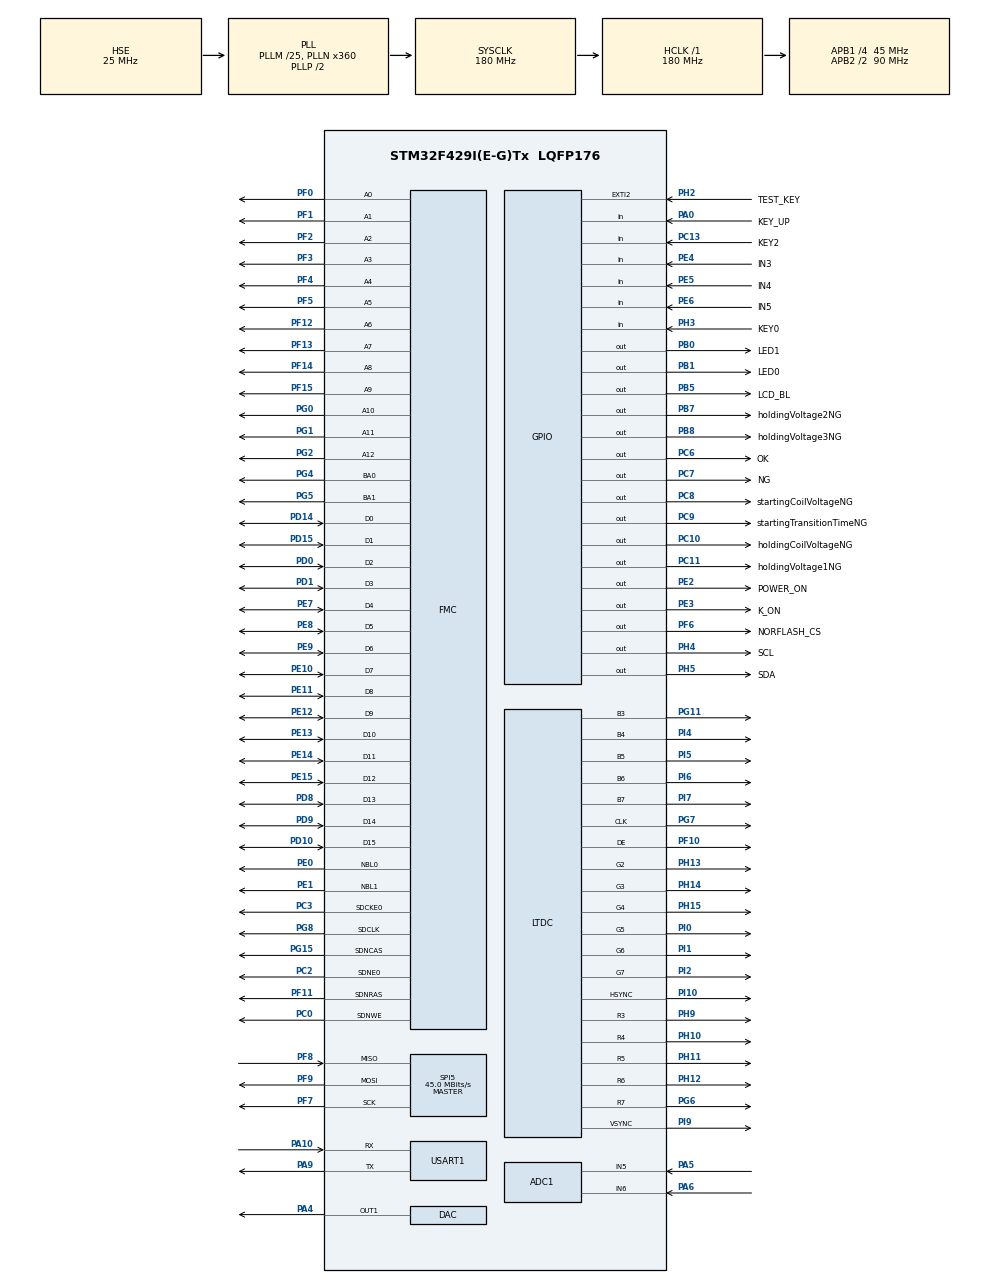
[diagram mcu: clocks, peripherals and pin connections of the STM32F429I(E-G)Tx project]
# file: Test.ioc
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ADC1.Channel-0\#ChannelRegularConversion=ADC_CHANNEL_5
ADC1.Channel-1\#ChannelRegularConversion=ADC_CHANNEL_6
ADC1.Channel-2\#ChannelRegularConversion=ADC_CHANNEL_TEMPSENSOR
ADC1.ContinuousConvMode=ENABLE
ADC1.DMAContinuousRequests=ENABLE
ADC1.EOCSelection=ADC_EOC_SEQ_CONV
ADC1.EnableAnalogWatchDog=true
ADC1.ExternalTrigConv=ADC_SOFTWARE_START
ADC1.HighThreshold=3000
ADC1.ITMode=ENABLE
ADC1.NbrOfConversion=3
ADC1.NbrOfConversionFlag=1
ADC1.Rank-0\#ChannelRegularConversion=1
ADC1.Rank-1\#ChannelRegularConversion=2
ADC1.Rank-2\#ChannelRegularConversion=3
ADC1.SamplingTime-0\#ChannelRegularConversion=ADC_SAMPLETIME_480CYCLES
ADC1.SamplingTime-1\#ChannelRegularConversion=ADC_SAMPLETIME_480CYCLES
ADC1.SamplingTime-2\#ChannelRegularConversion=ADC_SAMPLETIME_480CYCLES
ADC1.ScanConvMode=ENABLE
ADC1.WatchdogMode=ADC_ANALOGWATCHDOG_ALL_REG
ADC1.master=1
DAC.DAC_OutputBuffer=DAC_OUTPUTBUFFER_ENABLE
DMA2D.ColorMode=DMA2D_OUTPUT_RGB565
Dma.ADC1.0.Direction=DMA_PERIPH_TO_MEMORY
Dma.ADC1.0.FIFOMode=DMA_FIFOMODE_DISABLE
Dma.ADC1.0.Instance=DMA2_Stream0
Dma.ADC1.0.MemDataAlignment=DMA_MDATAALIGN_WORD
Dma.ADC1.0.MemInc=DMA_MINC_ENABLE
Dma.ADC1.0.Mode=DMA_CIRCULAR
Dma.ADC1.0.PeriphDataAlignment=DMA_PDATAALIGN_WORD
Dma.ADC1.0.PeriphInc=DMA_PINC_DISABLE
Dma.ADC1.0.Priority=DMA_PRIORITY_MEDIUM
Dma.Request0=ADC1
Dma.Request1=USART1_RX
Dma.Request2=USART1_TX
Dma.USART1_RX.1.Direction=DMA_PERIPH_TO_MEMORY
Dma.USART1_RX.1.FIFOMode=DMA_FIFOMODE_DISABLE
Dma.USART1_RX.1.Instance=DMA2_Stream2
Dma.USART1_RX.1.MemDataAlignment=DMA_MDATAALIGN_BYTE
Dma.USART1_RX.1.MemInc=DMA_MINC_ENABLE
Dma.USART1_RX.1.Mode=DMA_NORMAL
Dma.USART1_RX.1.PeriphDataAlignment=DMA_PDATAALIGN_BYTE
Dma.USART1_RX.1.PeriphInc=DMA_PINC_DISABLE
Dma.USART1_RX.1.Priority=DMA_PRIORITY_VERY_HIGH
Dma.USART1_TX.2.Direction=DMA_MEMORY_TO_PERIPH
Dma.USART1_TX.2.FIFOMode=DMA_FIFOMODE_DISABLE
Dma.USART1_TX.2.Instance=DMA2_Stream7
Dma.USART1_TX.2.MemDataAlignment=DMA_MDATAALIGN_BYTE
Dma.USART1_TX.2.MemInc=DMA_MINC_ENABLE
Dma.USART1_TX.2.Mode=DMA_NORMAL
Dma.USART1_TX.2.PeriphDataAlignment=DMA_PDATAALIGN_BYTE
Dma.USART1_TX.2.PeriphInc=DMA_PINC_DISABLE
Dma.USART1_TX.2.Priority=DMA_PRIORITY_VERY_HIGH
FATFS._CODE_PAGE=936
FATFS._FS_EXFAT=1
FATFS._FS_NORTC=0
FATFS._FS_RPATH=2
FATFS._LFN_UNICODE=0
FATFS._MAX_SS=4096
FATFS._NORTC_MDAY=25
FATFS._NORTC_MON=5
FATFS._NORTC_YEAR=2026
FATFS._USE_LFN=3
FMC.CASLatency1=FMC_SDRAM_CAS_LATENCY_3
FMC.ColumnBitsNumber1=FMC_SDRAM_COLUMN_BITS_NUM_9
FMC.ExitSelfRefreshDelay1=8
FMC.LoadToActiveDelay1=2
FMC.RCDDelay1=2
FMC.RPDelay1=2
FMC.RPDelay2=2
FMC.ReadBurst1=FMC_SDRAM_RBURST_ENABLE
FMC.ReadBurst2=FMC_SDRAM_RBURST_ENABLE
FMC.ReadPipeDelay1=FMC_SDRAM_RPIPE_DELAY_1
FMC.ReadPipeDelay2=FMC_SDRAM_RPIPE_DELAY_1
FMC.RowCycleDelay1=6
FMC.RowCycleDelay2=6
FMC.SDClockPeriod1=FMC_SDRAM_CLOCK_PERIOD_2
FMC.SDClockPeriod2=FMC_SDRAM_CLOCK_PERIOD_2
FMC.SelfRefreshTime1=6
FMC.WriteProtection1=FMC_SDRAM_WRITE_PROTECTION_DISABLE
FMC.WriteRecoveryTime1=4
FREERTOS.BinarySemaphores01=adcConversionCompleteSemaphore,Dynamic,NULL,;testStartSemaphore,Dynamic,NULL,Depleted;clearDisplaySemaphore,Dynamic,NULL,Depleted
FREERTOS.Tasks01=touchGFX,24,4096,TouchGFX_Task,As weak,NULL,Dynamic,NULL,NULL;adcTask,32,256,adcStartTask,Default,NULL,Dynamic,NULL,NULL;usart1Data,24,512,usart1DataTask,Default,NULL,Dynamic,NULL,NULL;dacTask,24,256,dacStartTask,Default,NULL,Dynamic,NULL,NULL;testTask,24,512,testStartTask,Default,NULL,Dynamic,NULL,NULL;vTaskSDCard,8,1024,SDCardManager,Default,NULL,Dynamic,NULL,NULL
FREERTOS.configENABLE_FPU=1
FREERTOS.configLIBRARY_MAX_SYSCALL_INTERRUPT_PRIORITY=2
FREERTOS.configTOTAL_HEAP_SIZE=102400
FREERTOS.configUSE_NEWLIB_REENTRANT=1
FREERTOS.copyHeapFile=1
LTDC.ActiveH=600
LTDC.ActiveW=1024
LTDC.Alpha_L0=255
LTDC.FBStartAdress_L0=0xC0000000
LTDC.HBP=140
LTDC.HFP=160
LTDC.HSync=20
LTDC.ImageHeight_L0=600
LTDC.ImageWidth_L0=1024
LTDC.Layers=0
LTDC.PixelFormat_L0=LTDC_PIXEL_FORMAT_RGB565
LTDC.VBP=20
LTDC.VFP=12
LTDC.VSync=3
LTDC.WindowX1_L0=1024
LTDC.WindowY1_L0=600
Mcu.Family=STM32F4
Mcu.Name=STM32F429I(E-G)Tx
Mcu.Package=LQFP176
NVIC.ADC_IRQn=true\:5\:0\:true\:false\:true\:true\:true\:true\:true
NVIC.DMA2D_IRQn=true\:9\:0\:true\:false\:true\:true\:true\:true\:true
NVIC.DMA2_Stream0_IRQn=true\:5\:0\:true\:false\:true\:true\:false\:true\:true
NVIC.DMA2_Stream2_IRQn=true\:6\:0\:true\:false\:true\:true\:false\:true\:true
NVIC.DMA2_Stream7_IRQn=true\:6\:0\:true\:false\:true\:true\:false\:true\:true
NVIC.EXTI2_IRQn=true\:2\:0\:false\:false\:true\:true\:true\:true\:true
NVIC.LTDC_IRQn=true\:9\:0\:true\:false\:true\:true\:true\:true\:true
NVIC.PriorityGroup=NVIC_PRIORITYGROUP_4
NVIC.TIM6_DAC_IRQn=true\:6\:0\:true\:false\:true\:true\:true\:true\:true
NVIC.TIM7_IRQn=true\:0\:0\:false\:false\:true\:false\:false\:true\:true
NVIC.TimeBase=TIM7_IRQn
NVIC.TimeBaseIP=TIM7
NVIC.USART1_IRQn=true\:6\:0\:true\:false\:true\:true\:true\:true\:true
PA0/WKUP.GPIO_Label=KEY_UP
PA0/WKUP.GPIO_PuPd=GPIO_PULLDOWN
PA0/WKUP.Signal=GPIO_Input
PA10.Mode=Asynchronous
PA10.Signal=USART1_RX
PA13.Mode=Serial_Wire
PA13.Signal=SYS_JTMS-SWDIO
PA14.Mode=Serial_Wire
PA14.Signal=SYS_JTCK-SWCLK
PA4.Signal=COMP_DAC1_group
PA5.Signal=ADCx_IN5
PA6.Signal=ADCx_IN6
PA9.Mode=Asynchronous
PA9.Signal=USART1_TX
PB0.GPIO_Label=LED1
PB0.GPIO_PuPd=GPIO_PULLUP
PB0.GPIO_Speed=GPIO_SPEED_FREQ_LOW
PB0.PinState=GPIO_PIN_SET
PB0.Signal=GPIO_Output
PB1.GPIO_Label=LED0
PB1.GPIO_PuPd=GPIO_PULLUP
PB1.GPIO_Speed=GPIO_SPEED_FREQ_LOW
PB1.PinState=GPIO_PIN_SET
PB1.Signal=GPIO_Output
PB5.GPIO_Label=LCD_BL
PB5.GPIO_PuPd=GPIO_PULLUP
PB5.GPIO_Speed=GPIO_SPEED_FREQ_HIGH
PB5.Signal=GPIO_Output
PB7.GPIO_Label=holdingVoltage2NG
PB7.GPIO_ModeDefaultOutputPP=GPIO_MODE_OUTPUT_PP
PB7.GPIO_PuPd=GPIO_PULLUP
PB7.GPIO_Speed=GPIO_SPEED_FREQ_HIGH
PB7.PinState=GPIO_PIN_SET
PB7.Signal=GPIO_Output
PB8.GPIO_Label=holdingVoltage3NG
PB8.GPIO_PuPd=GPIO_PULLUP
PB8.GPIO_Speed=GPIO_SPEED_FREQ_HIGH
PB8.PinState=GPIO_PIN_SET
PB8.Signal=GPIO_Output
PC0.Signal=FMC_SDNWE
PC10.GPIO_Label=holdingCoilVoltageNG
PC10.GPIO_PuPd=GPIO_PULLUP
PC10.GPIO_Speed=GPIO_SPEED_FREQ_HIGH
PC10.Signal=GPIO_Output
PC11.GPIO_Label=holdingVoltage1NG
PC11.GPIO_PuPd=GPIO_PULLUP
PC11.GPIO_Speed=GPIO_SPEED_FREQ_HIGH
PC11.Signal=GPIO_Output
PC13.GPIO_Label=KEY2
PC13.GPIO_PuPd=GPIO_PULLUP
PC13.Signal=GPIO_Input
PC14/OSC32_IN.Mode=LSE-External-Oscillator
PC14/OSC32_IN.Signal=RCC_OSC32_IN
PC15/OSC32_OUT.Mode=LSE-External-Oscillator
PC15/OSC32_OUT.Signal=RCC_OSC32_OUT
PC2.Mode=SdramChipSelect1_1
PC2.Signal=FMC_SDNE0
PC3.Mode=SdramChipSelect1_1
PC3.Signal=FMC_SDCKE0
PC6.GPIO_Label=OK
PC6.GPIO_PuPd=GPIO_PULLUP
PC6.GPIO_Speed=GPIO_SPEED_FREQ_HIGH
PC6.PinState=GPIO_PIN_SET
PC6.Signal=GPIO_Output
PC7.GPIO_Label=NG
PC7.GPIO_PuPd=GPIO_PULLUP
PC7.GPIO_Speed=GPIO_SPEED_FREQ_HIGH
PC7.PinState=GPIO_PIN_SET
PC7.Signal=GPIO_Output
PC8.GPIO_Label=startingCoilVoltageNG
PC8.GPIO_ModeDefaultOutputPP=GPIO_MODE_OUTPUT_PP
PC8.GPIO_PuPd=GPIO_PULLUP
PC8.GPIO_Speed=GPIO_SPEED_FREQ_HIGH
PC8.Signal=GPIO_Output
PC9.GPIO_Label=startingTransitionTimeNG
PC9.GPIO_PuPd=GPIO_PULLUP
PC9.GPIO_Speed=GPIO_SPEED_FREQ_HIGH
PC9.Signal=GPIO_Output
PD0.Signal=FMC_D2_DA2
PD1.Signal=FMC_D3_DA3
PD10.Signal=FMC_D15_DA15
PD14.Signal=FMC_D0_DA0
PD15.Signal=FMC_D1_DA1
PD8.Signal=FMC_D13_DA13
PD9.Signal=FMC_D14_DA14
PE0.Signal=FMC_NBL0
PE1.Signal=FMC_NBL1
PE10.Signal=FMC_D7_DA7
PE11.Signal=FMC_D8_DA8
PE12.Signal=FMC_D9_DA9
PE13.Signal=FMC_D10_DA10
PE14.Signal=FMC_D11_DA11
PE15.Signal=FMC_D12_DA12
PE2.GPIO_Label=POWER_ON
PE2.GPIO_PuPd=GPIO_PULLUP
PE2.GPIO_Speed=GPIO_SPEED_FREQ_LOW
PE2.PinState=GPIO_PIN_SET
PE2.Signal=GPIO_Output
PE3.GPIO_Label=K_ON
PE3.GPIO_ModeDefaultOutputPP=GPIO_MODE_OUTPUT_PP
PE3.GPIO_PuPd=GPIO_PULLDOWN
PE3.GPIO_Speed=GPIO_SPEED_FREQ_LOW
PE3.PinState=GPIO_PIN_RESET
PE3.Signal=GPIO_Output
PE4.GPIO_Label=IN3
PE4.GPIO_PuPd=GPIO_PULLUP
PE4.Signal=GPIO_Input
PE5.GPIO_Label=IN4
PE5.GPIO_PuPd=GPIO_PULLUP
PE5.Signal=GPIO_Input
PE6.GPIO_Label=IN5
PE6.GPIO_PuPd=GPIO_PULLUP
PE6.Signal=GPIO_Input
PE7.Signal=FMC_D4_DA4
PE8.Signal=FMC_D5_DA5
PE9.Signal=FMC_D6_DA6
PF0.Signal=FMC_A0
PF1.Signal=FMC_A1
PF10.GPIO_Speed=GPIO_SPEED_FREQ_VERY_HIGH
PF10.Mode=RGB565
PF10.Signal=LTDC_DE
PF11.Signal=FMC_SDNRAS
PF12.Signal=FMC_A6
PF13.Signal=FMC_A7
PF14.Signal=FMC_A8
PF15.Signal=FMC_A9
PF2.Signal=FMC_A2
PF3.Signal=FMC_A3
PF4.Signal=FMC_A4
PF5.Signal=FMC_A5
PF6.GPIO_Label=NORFLASH_CS
PF6.GPIO_PuPd=GPIO_PULLUP
PF6.GPIO_Speed=GPIO_SPEED_FREQ_HIGH
PF6.PinState=GPIO_PIN_SET
PF6.Signal=GPIO_Output
PF7.Mode=Full_Duplex_Master
PF7.Signal=SPI5_SCK
PF8.Mode=Full_Duplex_Master
PF8.Signal=SPI5_MISO
PF9.Mode=Full_Duplex_Master
PF9.Signal=SPI5_MOSI
PG0.Signal=FMC_A10
PG1.Signal=FMC_A11
PG11.GPIO_Speed=GPIO_SPEED_FREQ_VERY_HIGH
PG11.Mode=RGB565
PG11.Signal=LTDC_B3
PG15.Signal=FMC_SDNCAS
PG2.Signal=FMC_A12
PG4.Signal=FMC_A14_BA0
PG5.Signal=FMC_A15_BA1
PG6.GPIO_Speed=GPIO_SPEED_FREQ_VERY_HIGH
PG6.Mode=RGB565
PG6.Signal=LTDC_R7
PG7.GPIO_Speed=GPIO_SPEED_FREQ_VERY_HIGH
PG7.Mode=RGB565
PG7.Signal=LTDC_CLK
PG8.Signal=FMC_SDCLK
PH0/OSC_IN.Mode=HSE-External-Oscillator
PH0/OSC_IN.Signal=RCC_OSC_IN
PH1/OSC_OUT.Mode=HSE-External-Oscillator
PH1/OSC_OUT.Signal=RCC_OSC_OUT
PH10.GPIO_Speed=GPIO_SPEED_FREQ_VERY_HIGH
PH10.Mode=RGB565
PH10.Signal=LTDC_R4
PH11.GPIO_Speed=GPIO_SPEED_FREQ_VERY_HIGH
PH11.Mode=RGB565
PH11.Signal=LTDC_R5
PH12.GPIO_Speed=GPIO_SPEED_FREQ_VERY_HIGH
PH12.Mode=RGB565
PH12.Signal=LTDC_R6
PH13.GPIO_Speed=GPIO_SPEED_FREQ_VERY_HIGH
PH13.Mode=RGB565
PH13.Signal=LTDC_G2
PH14.GPIO_Speed=GPIO_SPEED_FREQ_VERY_HIGH
PH14.Mode=RGB565
PH14.Signal=LTDC_G3
PH15.GPIO_Speed=GPIO_SPEED_FREQ_VERY_HIGH
PH15.Mode=RGB565
PH15.Signal=LTDC_G4
PH2.GPIO_Label=TEST_KEY
PH2.GPIO_ModeDefaultEXTI=GPIO_MODE_IT_FALLING
PH2.GPIO_PuPd=GPIO_PULLUP
PH2.Signal=GPXTI2
PH3.GPIO_Label=KEY0
PH3.GPIO_PuPd=GPIO_PULLUP
PH3.Signal=GPIO_Input
PH4.GPIO_Label=SCL
PH4.GPIO_ModeDefaultOutputPP=GPIO_MODE_OUTPUT_OD
PH4.GPIO_PuPd=GPIO_PULLUP
PH4.GPIO_Speed=GPIO_SPEED_FREQ_HIGH
PH4.PinState=GPIO_PIN_SET
PH4.Signal=GPIO_Output
PH5.GPIO_Label=SDA
PH5.GPIO_ModeDefaultOutputPP=GPIO_MODE_OUTPUT_OD
PH5.GPIO_PuPd=GPIO_PULLUP
PH5.GPIO_Speed=GPIO_SPEED_FREQ_HIGH
PH5.PinState=GPIO_PIN_SET
PH5.Signal=GPIO_Output
PH9.GPIO_Speed=GPIO_SPEED_FREQ_VERY_HIGH
PH9.Mode=RGB565
PH9.Signal=LTDC_R3
PI0.GPIO_Speed=GPIO_SPEED_FREQ_VERY_HIGH
PI0.Mode=RGB565
PI0.Signal=LTDC_G5
PI1.GPIO_Speed=GPIO_SPEED_FREQ_VERY_HIGH
PI1.Mode=RGB565
PI1.Signal=LTDC_G6
PI10.GPIO_Speed=GPIO_SPEED_FREQ_VERY_HIGH
PI10.Mode=RGB565
PI10.Signal=LTDC_HSYNC
PI2.GPIO_Speed=GPIO_SPEED_FREQ_VERY_HIGH
PI2.Mode=RGB565
PI2.Signal=LTDC_G7
PI4.GPIO_Speed=GPIO_SPEED_FREQ_VERY_HIGH
PI4.Mode=RGB565
PI4.Signal=LTDC_B4
PI5.GPIO_Speed=GPIO_SPEED_FREQ_VERY_HIGH
PI5.Mode=RGB565
PI5.Signal=LTDC_B5
PI6.GPIO_Speed=GPIO_SPEED_FREQ_VERY_HIGH
PI6.Mode=RGB565
PI6.Signal=LTDC_B6
PI7.GPIO_Speed=GPIO_SPEED_FREQ_VERY_HIGH
PI7.Mode=RGB565
PI7.Signal=LTDC_B7
PI9.GPIO_Speed=GPIO_SPEED_FREQ_VERY_HIGH
PI9.Mode=RGB565
PI9.Signal=LTDC_VSYNC
ProjectManager.HeapSize=0x2000
ProjectManager.StackSize=0x1000
ProjectManager.TargetToolchain=STM32CubeIDE
RCC.48MHZClocksFreq_Value=45000000
RCC.AHBFreq_Value=180000000
RCC.APB1CLKDivider=RCC_HCLK_DIV4
RCC.APB1Freq_Value=45000000
RCC.APB1TimFreq_Value=90000000
RCC.APB2CLKDivider=RCC_HCLK_DIV2
RCC.APB2Freq_Value=90000000
RCC.APB2TimFreq_Value=180000000
RCC.CortexFreq_Value=180000000
RCC.HCLKFreq_Value=180000000
RCC.HSE_VALUE=25000000
RCC.HSI_VALUE=16000000
RCC.PLLM=25
RCC.PLLN=360
RCC.PLLQ=8
RCC.PLLSAIN=168
RCC.PLLSAIR=2
RCC.PLLSourceVirtual=RCC_PLLSOURCE_HSE
RCC.RCC_RTC_Clock_Source=RCC_RTCCLKSOURCE_LSE
RCC.RCC_RTC_Clock_SourceVirtual=RCC_RTCCLKSOURCE_LSE
RCC.SYSCLKFreq_VALUE=180000000
RCC.SYSCLKSource=RCC_SYSCLKSOURCE_PLLCLK
RCC.VCOOutputFreq_Value=360000000
RTC.Alarm=RTC_ALARM_A
RTC.Alarm_B=RTC_ALARM_B
RTC.Date=25
RTC.Format=RTC_FORMAT_BIN
RTC.Hours=15
RTC.Minutes=25
RTC.Month=RTC_MONTH_MAY
RTC.WeekDay=RTC_WEEKDAY_SUNDAY
RTC.Year=25
SH.ADCx_IN5.0=ADC1_IN5,IN5
SH.ADCx_IN6.0=ADC1_IN6,IN6
SH.COMP_DAC1_group.0=DAC_OUT1,DAC_OUT1
SH.FMC_A0.0=FMC_A0,13b-sda1
SH.FMC_A1.0=FMC_A1,13b-sda1
SH.FMC_A10.0=FMC_A10,13b-sda1
SH.FMC_A11.0=FMC_A11,13b-sda1
SH.FMC_A12.0=FMC_A12,13b-sda1
SH.FMC_A14_BA0.0=FMC_BA0,FourSdramBanks1
SH.FMC_A15_BA1.0=FMC_BA1,FourSdramBanks1
SH.FMC_A2.0=FMC_A2,13b-sda1
SH.FMC_A3.0=FMC_A3,13b-sda1
SH.FMC_A4.0=FMC_A4,13b-sda1
SH.FMC_A5.0=FMC_A5,13b-sda1
SH.FMC_A6.0=FMC_A6,13b-sda1
SH.FMC_A7.0=FMC_A7,13b-sda1
SH.FMC_A8.0=FMC_A8,13b-sda1
SH.FMC_A9.0=FMC_A9,13b-sda1
SH.FMC_D0_DA0.0=FMC_D0,sd-16b-d1
SH.FMC_D10_DA10.0=FMC_D10,sd-16b-d1
SH.FMC_D11_DA11.0=FMC_D11,sd-16b-d1
SH.FMC_D12_DA12.0=FMC_D12,sd-16b-d1
SH.FMC_D13_DA13.0=FMC_D13,sd-16b-d1
SH.FMC_D14_DA14.0=FMC_D14,sd-16b-d1
SH.FMC_D15_DA15.0=FMC_D15,sd-16b-d1
SH.FMC_D1_DA1.0=FMC_D1,sd-16b-d1
SH.FMC_D2_DA2.0=FMC_D2,sd-16b-d1
SH.FMC_D3_DA3.0=FMC_D3,sd-16b-d1
SH.FMC_D4_DA4.0=FMC_D4,sd-16b-d1
SH.FMC_D5_DA5.0=FMC_D5,sd-16b-d1
SH.FMC_D6_DA6.0=FMC_D6,sd-16b-d1
SH.FMC_D7_DA7.0=FMC_D7,sd-16b-d1
SH.FMC_D8_DA8.0=FMC_D8,sd-16b-d1
SH.FMC_D9_DA9.0=FMC_D9,sd-16b-d1
SH.FMC_NBL0.0=FMC_NBL0,Sd2ByteEnable1
SH.FMC_NBL1.0=FMC_NBL1,Sd2ByteEnable1
SH.FMC_SDCLK.0=FMC_SDCLK,13b-sda1
SH.FMC_SDNCAS.0=FMC_SDNCAS,13b-sda1
SH.FMC_SDNRAS.0=FMC_SDNRAS,13b-sda1
SH.FMC_SDNWE.0=FMC_SDNWE,13b-sda1
SPI5.BaudRatePrescaler=SPI_BAUDRATEPRESCALER_2
SPI5.CLKPhase=SPI_PHASE_2EDGE
SPI5.CLKPolarity=SPI_POLARITY_HIGH
SPI5.CalculateBaudRate=45.0 MBits/s
SPI5.Direction=SPI_DIRECTION_2LINES
SPI5.Mode=SPI_MODE_MASTER
SPI5.VirtualType=VM_MASTER
STMicroelectronics.X-CUBE-TOUCHGFX.4.26.0.ApplicationCcGraphicsJjApplication=TouchGFXOoGenerator
STMicroelectronics.X-CUBE-TOUCHGFX.4.26.0.tgfx_address1=0xC0000000
STMicroelectronics.X-CUBE-TOUCHGFX.4.26.0.tgfx_address2=0xC012C000
STMicroelectronics.X-CUBE-TOUCHGFX.4.26.0.tgfx_buffering_strategy=Double
STMicroelectronics.X-CUBE-TOUCHGFX.4.26.0.tgfx_display_interface=disp_ltdc
STMicroelectronics.X-CUBE-TOUCHGFX.4.26.0.tgfx_framebuffer_stride=Enabled
STMicroelectronics.X-CUBE-TOUCHGFX.4.26.0.tgfx_hardware_accelerator=dma_2d
STMicroelectronics.X-CUBE-TOUCHGFX.4.26.0.tgfx_location=By Address
STMicroelectronics.X-CUBE-TOUCHGFX.4.26.0.tgfx_nema_cl_size=8192
STMicroelectronics.X-CUBE-TOUCHGFX.4.26.0.tgfx_vsync=vsync_ltdc
STMicroelectronics.X-CUBE-TOUCHGFX.4.26.0_IsPackSelfContextualization=true
USART1.VirtualMode=VM_ASYNC
VP_ADC1_TempSens_Input.Mode=IN-TempSens
VP_CRC_VS_CRC.Mode=CRC_Activate
VP_DMA2D_VS_DMA2D.Mode=DMA2D_Activate
VP_FATFS_VS_Generic.Mode=User_defined
VP_FREERTOS_VS_CMSIS_V2.Mode=CMSIS_V2
VP_RTC_VS_RTC_Activate.Mode=RTC_Enabled
VP_RTC_VS_RTC_Alarm_A_Intern.Mode=Alarm A
VP_RTC_VS_RTC_Alarm_B_Intern.Mode=Alarm B
VP_RTC_VS_RTC_Calendar.Mode=RTC_Calendar
VP_STMicroelectronics.X-CUBE-TOUCHGFX_VS_GraphicsJjApplication_4.26.0.Mode=GraphicsJjApplication
VP_SYS_VS_tim7.Mode=TIM7
VP_TIM3_VS_ClockSourceINT.Mode=Internal
board=custom

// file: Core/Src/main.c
/* USER CODE BEGIN Header */
/**
  ******************************************************************************
  * @file           : main.c
  * @brief          : Main program body
  ******************************************************************************
  * @attention
  *
  * Copyright (c) 2023 STMicroelectronics.
  * All rights reserved.
  *
  * This software is licensed under terms that can be found in the LICENSE file
  * in the root directory of this software component.
  * If no LICENSE file comes with this software, it is provided AS-IS.
  *
  ******************************************************************************
  */
/* USER CODE END Header */
#include "main.h"
#include "cmsis_os.h"
#include "adc.h"
#include "crc.h"
#include "dac.h"
#include "dma.h"
#include "dma2d.h"
#include "fatfs.h"
#include "ltdc.h"
#include "rtc.h"
#include "spi.h"
#include "tim.h"
#include "usart.h"
#include "gpio.h"
#include "fmc.h"
#include "app_touchgfx.h"

/* USER CODE BEGIN Includes */
#include "stdio.h"
#include "test.h"
/* USER CODE END Includes */

void SystemClock_Config(void);
void MX_FREERTOS_Init(void);

int main(void)
{

  /* MCU Configuration--------------------------------------------------------*/

  /* Reset of all peripherals, Initializes the Flash interface and the Systick. */
  HAL_Init();

  /* Configure the system clock */
  SystemClock_Config();

  /* Initialize all configured peripherals */
  MX_GPIO_Init();
  MX_DMA_Init();
  MX_DMA2D_Init();
  MX_FMC_Init();
  MX_CRC_Init();
  MX_LTDC_Init();
  MX_ADC1_Init();
  MX_USART1_UART_Init();
  MX_RTC_Init();
  MX_TIM3_Init();
  MX_DAC_Init();
  MX_SPI5_Init();
  MX_FATFS_Init();
  MX_TouchGFX_Init();
  /* Call PreOsInit function */
  MX_TouchGFX_PreOSInit();
  /* USER CODE BEGIN 2 */
	// ------- 锟斤拷锟角耙伙拷尾锟斤拷缘锟絀O状态锟酵碉拷状态 -------
  HAL_GPIO_WritePin(LED0_GPIO_Port, LED0_Pin, GPIO_PIN_SET);   // 锟截憋拷锟斤拷锟斤拷锟�
  HAL_GPIO_WritePin(OK_GPIO_Port, OK_Pin, GPIO_PIN_SET);       // 锟截憋拷OK锟斤拷锟�
  HAL_GPIO_WritePin(NG_GPIO_Port, NG_Pin, GPIO_PIN_SET);       // 锟截憋拷NG锟斤拷锟�

  HAL_GPIO_WritePin(startingCoilVoltageNG_GPIO_Port, startingCoilVoltageNG_Pin, GPIO_PIN_SET);
  HAL_GPIO_WritePin(holdingCoilVoltageNG_GPIO_Port, holdingCoilVoltageNG_Pin, GPIO_PIN_SET);
  HAL_GPIO_WritePin(startingTransitionTimeNG_GPIO_Port, startingTransitionTimeNG_Pin, GPIO_PIN_SET);
  HAL_GPIO_WritePin(holdingVoltage1NG_GPIO_Port, holdingVoltage1NG_Pin, GPIO_PIN_SET);
  HAL_GPIO_WritePin(holdingVoltage2NG_GPIO_Port, holdingVoltage2NG_Pin, GPIO_PIN_SET);
  HAL_GPIO_WritePin(holdingVoltage3NG_GPIO_Port, holdingVoltage3NG_Pin, GPIO_PIN_SET);
  HAL_GPIO_WritePin(K_ON_GPIO_Port, K_ON_Pin, GPIO_PIN_RESET); // 默认分压20:1

  HAL_DAC_Start(&hdac, DAC_CHANNEL_1);
  HAL_DAC_SetValue(&hdac, DAC_CHANNEL_1, DAC_ALIGN_12B_R, 0);

  InitOrLoadStatistics(&productionCount);
  /* USER CODE END 2 */

  /* Init scheduler */
  osKernelInitialize();  /* Call init function for freertos objects (in cmsis_os2.c) */
  MX_FREERTOS_Init();

  /* Start scheduler */
  osKernelStart();

  /* We should never get here as control is now taken by the scheduler */

  /* Infinite loop */
  while (1)
  {

  }
}

void SystemClock_Config(void)
{
  RCC_OscInitTypeDef RCC_OscInitStruct = {0};
  RCC_ClkInitTypeDef RCC_ClkInitStruct = {0};

  /** Configure the main internal regulator output voltage
  */
  __HAL_RCC_PWR_CLK_ENABLE();
  __HAL_PWR_VOLTAGESCALING_CONFIG(PWR_REGULATOR_VOLTAGE_SCALE1);

  /** Initializes the RCC Oscillators according to the specified parameters
  * in the RCC_OscInitTypeDef structure.
  */
  RCC_OscInitStruct.OscillatorType = RCC_OSCILLATORTYPE_HSE|RCC_OSCILLATORTYPE_LSE;
  RCC_OscInitStruct.HSEState = RCC_HSE_ON;
  RCC_OscInitStruct.LSEState = RCC_LSE_ON;
  RCC_OscInitStruct.PLL.PLLState = RCC_PLL_ON;
  RCC_OscInitStruct.PLL.PLLSource = RCC_PLLSOURCE_HSE;
  RCC_OscInitStruct.PLL.PLLM = 25;
  RCC_OscInitStruct.PLL.PLLN = 360;
  RCC_OscInitStruct.PLL.PLLP = RCC_PLLP_DIV2;
  RCC_OscInitStruct.PLL.PLLQ = 8;
  if (HAL_RCC_OscConfig(&RCC_OscInitStruct) != HAL_OK)
  {
    Error_Handler();
  }

  /** Activate the Over-Drive mode
  */
  if (HAL_PWREx_EnableOverDrive() != HAL_OK)
  {
    Error_Handler();
  }

  /** Initializes the CPU, AHB and APB buses clocks
  */
  RCC_ClkInitStruct.ClockType = RCC_CLOCKTYPE_HCLK|RCC_CLOCKTYPE_SYSCLK
                              |RCC_CLOCKTYPE_PCLK1|RCC_CLOCKTYPE_PCLK2;
  RCC_ClkInitStruct.SYSCLKSource = RCC_SYSCLKSOURCE_PLLCLK;
  RCC_ClkInitStruct.AHBCLKDivider = RCC_SYSCLK_DIV1;
  RCC_ClkInitStruct.APB1CLKDivider = RCC_HCLK_DIV4;
  RCC_ClkInitStruct.APB2CLKDivider = RCC_HCLK_DIV2;

  if (HAL_RCC_ClockConfig(&RCC_ClkInitStruct, FLASH_LATENCY_5) != HAL_OK)
  {
    Error_Handler();
  }
}

void HAL_TIM_PeriodElapsedCallback(TIM_HandleTypeDef *htim)
{
  if (htim->Instance == TIM7)
  {
    HAL_IncTick();
  }
}

void Error_Handler(void)
{
  __disable_irq();
  while (1)
  {
  }
}

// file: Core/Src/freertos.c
/* USER CODE BEGIN Header */
/**
 ******************************************************************************
 * File Name          : freertos.c
 * Description        : Code for freertos applications
 ******************************************************************************
 * @attention
 *
 * Copyright (c) 2023 STMicroelectronics.
 * All rights reserved.
 *
 * This software is licensed under terms that can be found in the LICENSE file
 * in the root directory of this software component.
 * If no LICENSE file comes with this software, it is provided AS-IS.
 *
 ******************************************************************************
 */
/* USER CODE END Header */

#include "FreeRTOS.h"
#include "task.h"
#include "main.h"
#include "cmsis_os.h"

/* USER CODE BEGIN Includes */
#include "test.h"
#include "key.h"
#include "adc.h"
#include "dac.h"
#include "usart.h"
#include "stdio.h"
#include "stdbool.h"
#include "norflash.h"
#include "norflashmanager.h"
#include "soft_i2c.h"
#include "at24c02.h"
#include "ads1115.h"

/* USER CODE END Includes */

/* USER CODE BEGIN PTD */
extern SoftI2C_HandleTypeDef hi2c_eeprom;
/* USER CODE END PTD */

/* USER CODE BEGIN PD */

extern UART_HandleTypeDef huart1;

int __io_putchar(int ch) {
	HAL_UART_Transmit(&huart1, (uint8_t*) &ch, 1, HAL_MAX_DELAY);
	return ch;
}

/* USER CODE END PD */

/* Definitions for touchGFX */
osThreadId_t touchGFXHandle;
const osThreadAttr_t touchGFX_attributes = {
  .name = "touchGFX",
  .stack_size = 4096 * 4,
  .priority = (osPriority_t) osPriorityNormal,
};
/* Definitions for adcTask */
osThreadId_t adcTaskHandle;
const osThreadAttr_t adcTask_attributes = {
  .name = "adcTask",
  .stack_size = 256 * 4,
  .priority = (osPriority_t) osPriorityAboveNormal,
};
/* Definitions for usart1Data */
osThreadId_t usart1DataHandle;
const osThreadAttr_t usart1Data_attributes = {
  .name = "usart1Data",
  .stack_size = 512 * 4,
  .priority = (osPriority_t) osPriorityNormal,
};
/* Definitions for dacTask */
osThreadId_t dacTaskHandle;
const osThreadAttr_t dacTask_attributes = {
  .name = "dacTask",
  .stack_size = 256 * 4,
  .priority = (osPriority_t) osPriorityNormal,
};
/* Definitions for testTask */
osThreadId_t testTaskHandle;
const osThreadAttr_t testTask_attributes = {
  .name = "testTask",
  .stack_size = 512 * 4,
  .priority = (osPriority_t) osPriorityNormal,
};
/* Definitions for vTaskSDCard */
osThreadId_t vTaskSDCardHandle;
const osThreadAttr_t vTaskSDCard_attributes = {
  .name = "vTaskSDCard",
  .stack_size = 1024 * 4,
  .priority = (osPriority_t) osPriorityLow,
};
/* Definitions for adcConversionCompleteSemaphore */
osSemaphoreId_t adcConversionCompleteSemaphoreHandle;
const osSemaphoreAttr_t adcConversionCompleteSemaphore_attributes = {
  .name = "adcConversionCompleteSemaphore"
};
/* Definitions for testStartSemaphore */
osSemaphoreId_t testStartSemaphoreHandle;
const osSemaphoreAttr_t testStartSemaphore_attributes = {
  .name = "testStartSemaphore"
};
/* Definitions for clearDisplaySemaphore */
osSemaphoreId_t clearDisplaySemaphoreHandle;
const osSemaphoreAttr_t clearDisplaySemaphore_attributes = {
  .name = "clearDisplaySemaphore"
};

void TouchGFX_Task(void *argument);
void adcStartTask(void *argument);
void usart1DataTask(void *argument);
void dacStartTask(void *argument);
void testStartTask(void *argument);
void SDCardManager(void *argument);

void MX_FREERTOS_Init(void); /* (MISRA C 2004 rule 8.1) */

void MX_FREERTOS_Init(void) {

  /* Create the semaphores(s) */
  /* creation of adcConversionCompleteSemaphore */
  adcConversionCompleteSemaphoreHandle = osSemaphoreNew(1, 0, &adcConversionCompleteSemaphore_attributes);

  /* creation of testStartSemaphore */
  testStartSemaphoreHandle = osSemaphoreNew(1, 0, &testStartSemaphore_attributes);

  /* creation of clearDisplaySemaphore */
  clearDisplaySemaphoreHandle = osSemaphoreNew(1, 0, &clearDisplaySemaphore_attributes);

  /* Create the thread(s) */
  /* creation of touchGFX */
  touchGFXHandle = osThreadNew(TouchGFX_Task, NULL, &touchGFX_attributes);

  /* creation of adcTask */
  adcTaskHandle = osThreadNew(adcStartTask, NULL, &adcTask_attributes);

  /* creation of usart1Data */
  usart1DataHandle = osThreadNew(usart1DataTask, NULL, &usart1Data_attributes);

  /* creation of dacTask */
  dacTaskHandle = osThreadNew(dacStartTask, NULL, &dacTask_attributes);

  /* creation of testTask */
  testTaskHandle = osThreadNew(testStartTask, NULL, &testTask_attributes);

  /* creation of vTaskSDCard */
  vTaskSDCardHandle = osThreadNew(SDCardManager, NULL, &vTaskSDCard_attributes);

}

__weak void TouchGFX_Task(void *argument)
{
	for (;;) {
		osDelay(1);
	}
}

void adcStartTask(void *argument)
{
  /* USER CODE BEGIN adcStartTask */
	/* Infinite loop */

	HAL_ADC_Start_DMA(&hadc1, adc_buffer, ADC_BUFFER_SIZE * 3);

	for (;;) {
//	    	HandleADCData();
//
//	        // 等待DMA完成信号
//	        if (osSemaphoreAcquire(adcConversionCompleteSemaphoreHandle, osWaitForever) == osOK) {
//
//	        	HandleADCData();
//	        }

		osDelay(10);
	}

  /* USER CODE END adcStartTask */
}

void usart1DataTask(void *argument)
{
	for (;;) {
		osDelay(1);
	}
}

void dacStartTask(void *argument)
{
  /* USER CODE BEGIN dacStartTask */
	HAL_DAC_Start(&hdac, DAC_CHANNEL_1);

//  /* Infinite loop */
	for (;;) {

//	    osSemaphoreAcquire(testStartSemaphoreHandle, osWaitForever);  // 等待信号量
//
//		 dacValue = voltageToDAC(parameters[number].ratedVoltage);
//		 dacOut1 = parameters[number].ratedVoltage;
//		 HAL_DAC_SetValue(&hdac, DAC_CHANNEL_1, DAC_ALIGN_12B_R, dacValue); // 2048  DAC       ֵ
//		 HAL_DAC_Start(&hdac, DAC_CHANNEL_1);
//		 osDelay(500);
//		 HandleADCData();
//
//		 dacValue = voltageToDAC(parameters[number].inputVoltage1);
//		 dacOut1 = parameters[number].inputVoltage1;
//		 HAL_DAC_SetValue(&hdac, DAC_CHANNEL_1, DAC_ALIGN_12B_R, dacValue); // 2048  DAC       ֵ
//		 HAL_DAC_Start(&hdac, DAC_CHANNEL_1);
//		 osDelay(500);
//		 HandleADCData();
//
//		 dacValue = voltageToDAC(parameters[number].inputVoltage2);
//		 dacOut1 = parameters[number].inputVoltage2;
//		 HAL_DAC_SetValue(&hdac, DAC_CHANNEL_1, DAC_ALIGN_12B_R, dacValue); // 2048  DAC       ֵ
//		 HAL_DAC_Start(&hdac, DAC_CHANNEL_1);
//		 osDelay(500);
//		 HandleADCData();
//
//		 dacValue = voltageToDAC(parameters[number].inputVoltage3);
//		 dacOut1 = parameters[number].inputVoltage3;
//		 HAL_DAC_SetValue(&hdac, DAC_CHANNEL_1, DAC_ALIGN_12B_R, dacValue); // 2048  DAC       ֵ
//		 HAL_DAC_Start(&hdac, DAC_CHANNEL_1);
//		 osDelay(500);
//		 HandleADCData();
//
//
//
//		 // 以此类推……

		osDelay(1);
	}
  /* USER CODE END dacStartTask */
}

void testStartTask(void *argument)
{
  /* USER CODE BEGIN testStartTask */
	InitOrLoadStatistics(&productionCount);

	/* Infinite loop */
	for (;;) {
		// 等待UI或按键触发测试开始
		if (osSemaphoreAcquire(testStartSemaphoreHandle, osWaitForever)
				== osOK) {
			bool ok = true;  								// 用于记录测试是否通过，默认为通过

			// ------- 在每次测试前重置不良标志 -------
			currentResult.testFinished = false; 			// 重置测试完成标志
			currentResult.testPassed = false; 				// 重置测试通过标志
			currentResult.startingCoilVoltageNG = false;  	// 重置启动线圈电压不良标志
			currentResult.holdingCoilVoltageNG = false;     // 重置保持线圈电压不良标志
			currentResult.startingCoiltestFinished = false; // 重置测试完成标志
			currentResult.holdingVoltage1NG = false;     	// 重置保持电压1不良标志
			currentResult.holdingVoltage2NG = false;     	// 重置保持电压2不良标志
			currentResult.holdingVoltage3NG = false;     	// 重置保持电压3不良标志
			//currentResult.startingTransitionTimeNG = false; // 重置启动转换时间不良标志
			currentResult.startingTransitionNG = false; 	// 重置启动转换不良标志

			// ------- 清除前一次测试的IO状态和灯状态 -------
			HAL_GPIO_WritePin(LED0_GPIO_Port, LED0_Pin, GPIO_PIN_SET); // 关闭电压输出指示灯输出灯
			HAL_GPIO_WritePin(POWER_ON_GPIO_Port, POWER_ON_Pin, GPIO_PIN_SET); // 关闭电压输出
			HAL_GPIO_WritePin(OK_GPIO_Port, OK_Pin, GPIO_PIN_SET);     // 关闭OK输出
			HAL_GPIO_WritePin(NG_GPIO_Port, NG_Pin, GPIO_PIN_SET);     // 关闭NG输出

			HAL_GPIO_WritePin(startingCoilVoltageNG_GPIO_Port,
			startingCoilVoltageNG_Pin, GPIO_PIN_SET);
			HAL_GPIO_WritePin(holdingCoilVoltageNG_GPIO_Port,
			holdingCoilVoltageNG_Pin, GPIO_PIN_SET);
			HAL_GPIO_WritePin(startingTransitionTimeNG_GPIO_Port,
			startingTransitionTimeNG_Pin, GPIO_PIN_SET);
			HAL_GPIO_WritePin(holdingVoltage1NG_GPIO_Port,
			holdingVoltage1NG_Pin, GPIO_PIN_SET);
			HAL_GPIO_WritePin(holdingVoltage2NG_GPIO_Port,
			holdingVoltage2NG_Pin, GPIO_PIN_SET);
			HAL_GPIO_WritePin(holdingVoltage3NG_GPIO_Port,
			holdingVoltage3NG_Pin, GPIO_PIN_SET);

//			// ------- 第一步：输出设定电压到DAC，检测两路电压是否合格 -------
//			dacValue = voltageToDAC(parameters[number].ratedVoltage);				//输出额定电压
//			HAL_DAC_SetValue(&hdac, DAC_CHANNEL_1, DAC_ALIGN_12B_R, dacValue); 		// 设置DAC输出
//			osDelay(200);  // 等待电压稳定
//			HAL_GPIO_WritePin(POWER_ON_GPIO_Port, POWER_ON_Pin, GPIO_PIN_RESET); 	// 打开电压输出
//			HAL_GPIO_WritePin(LED0_GPIO_Port, LED0_Pin, GPIO_PIN_RESET); 			// 打开输出灯
//			uint32_t startTick = osKernelGetTickCount();
//			uint32_t detectedTick = 0;
//			bool fallingEdgeDetected = false;
//
//			// 进入检测循环，直到超时或检测到下降沿
//			while ((osKernelGetTickCount() - startTick) < parameters[number].startingTransitionTimeUpperLimit) {
//			    // 采样
//				HandleADCData();
//			    parameters[number].startingCoilVoltage = voltageIn5 * 20;  // *20 分压还原
//			    parameters[number].holdingCoilVoltage = voltageIn6 * 20;
//
//			    // 检查启动线圈电压是否在合格范围
//			    if (parameters[number].startingCoilVoltage < parameters[number].startingCoilVoltageLowerLimit ||
//			        parameters[number].startingCoilVoltage > parameters[number].startingCoilVoltageUpperLimit) {
//			        currentResult.startingCoilVoltageNG = true;
//			        HAL_GPIO_WritePin(startingCoilVoltageNG_GPIO_Port, startingCoilVoltageNG_Pin, GPIO_PIN_RESET);
//			        ok = false;
//			    }
//
//			    // 检查保持电压是否在合格范围
//			    if (parameters[number].holdingCoilVoltage < parameters[number].holdingCoilVoltageLowerLimit ||
//			        parameters[number].holdingCoilVoltage > parameters[number].holdingCoilVoltageUpperLimit) {
//			        currentResult.holdingCoilVoltageNG = true;
//			        HAL_GPIO_WritePin(holdingCoilVoltageNG_GPIO_Port, holdingCoilVoltageNG_Pin, GPIO_PIN_RESET);
//			        ok = false;
//			    }
//
//			    // 检测 startingCoilVoltage 是否首次低于下限，记录时间
//			    if (!fallingEdgeDetected &&
//			        parameters[number].startingCoilVoltage <= parameters[number].startingCoilVoltageLowerLimit) {
//			        detectedTick = osKernelGetTickCount();
//			        fallingEdgeDetected = true;
//			    }
//
//			    if (fallingEdgeDetected) break; // 检测到后退出
//			    osDelay(5);
//			}
//
//			// 检查结果，记录时间
//			if (!fallingEdgeDetected) {
//			    // 超时未检测到下降沿
//			    currentResult.startingTransitionTimeNG = true;
//			    HAL_GPIO_WritePin(startingTransitionTimeNG_GPIO_Port, startingTransitionTimeNG_Pin, GPIO_PIN_RESET);
//			    ok = false;
//			    parameters[number].startingTransitionTime = parameters[number].startingTransitionTimeUpperLimit;
//			} else {
//			    uint32_t delta = detectedTick - startTick;
//			    parameters[number].startingTransitionTime = delta;
//
//			    if (delta < parameters[number].startingTransitionTimeLowerLimit ||
//			        delta > parameters[number].startingTransitionTimeUpperLimit) {
//			        currentResult.startingTransitionTimeNG = true;
//			        HAL_GPIO_WritePin(startingTransitionTimeNG_GPIO_Port, startingTransitionTimeNG_Pin, GPIO_PIN_RESET);
//			        ok = false;
//			    }
//			}
			osDelay(10);
			// ------- 第一步：输出设定电压到DAC，检测两路电压是否合格 -------
			dacValue = voltageToDAC(parameters[number].ratedVoltage);	//输出额定电压
			HAL_DAC_SetValue(&hdac, DAC_CHANNEL_1, DAC_ALIGN_12B_R, dacValue); // 设置DAC输出
			osDelay(200);  // 等待电压稳定
			HAL_GPIO_WritePin(POWER_ON_GPIO_Port, POWER_ON_Pin, GPIO_PIN_RESET); // 打开电压输出
			HAL_GPIO_WritePin(LED0_GPIO_Port, LED0_Pin, GPIO_PIN_RESET); // 打开输出灯

			osDelay(parameters[number].startingTransitionTimeLowerLimit);
			if (osSemaphoreAcquire(adcConversionCompleteSemaphoreHandle, 100)
					== osOK) {
				HandleADCData();
				parameters[number].startingCoilVoltage = voltageIn5 * 20.4;
				if (parameters[number].startingCoilVoltage
						< parameters[number].startingCoilVoltageLowerLimit
						|| parameters[number].startingCoilVoltage
								> parameters[number].startingCoilVoltageUpperLimit) {
					currentResult.startingCoilVoltageNG = true;
					HAL_GPIO_WritePin(startingCoilVoltageNG_GPIO_Port,
					startingCoilVoltageNG_Pin, GPIO_PIN_RESET);
					ok = false;
				}

			} else {
				ok = false;
				currentResult.startingCoilVoltageNG = true;  // 设置不良标志
			}

			if (osSemaphoreAcquire(adcConversionCompleteSemaphoreHandle, 100)
					== osOK) {
				HandleADCData();
				parameters[number].holdingCoilVoltage = voltageIn6 * 20.2;
				// 检查保持电压是否在合格范围
				if (parameters[number].holdingCoilVoltage
						< parameters[number].holdingCoilVoltageLowerLimit
						|| parameters[number].holdingCoilVoltage
								> parameters[number].holdingCoilVoltageUpperLimit) {
					currentResult.holdingCoilVoltageNG = true;
					HAL_GPIO_WritePin(holdingCoilVoltageNG_GPIO_Port,
					holdingCoilVoltageNG_Pin, GPIO_PIN_RESET);
					ok = false;
				}

			} else {
				ok = false;
				currentResult.holdingCoilVoltageNG = true;
			}

			osDelay(
					parameters[number].startingTransitionTimeUpperLimit
							- parameters[number].startingTransitionTimeLowerLimit);
			if (osSemaphoreAcquire(adcConversionCompleteSemaphoreHandle, 100)
					== osOK) {
				HandleADCData();
				float startingCoilOffVoltage = voltageIn5 * 20.3;
				if (startingCoilOffVoltage > 1) {
					currentResult.startingTransitionNG = true;
					HAL_GPIO_WritePin(startingTransitionTimeNG_GPIO_Port,
							startingTransitionTimeNG_Pin, GPIO_PIN_RESET);
					ok = false;
				}

			} else {
				ok = false;
				currentResult.startingCoilVoltageNG = true;  // 设置不良标志
			}

			currentResult.startingCoiltestFinished = true;

			// ------- 第二步：输出输入电压1，检测保持电压1（PA6） -------
			dacValue = voltageToDAC(parameters[number].inputVoltage1);
			HAL_DAC_SetValue(&hdac, DAC_CHANNEL_1, DAC_ALIGN_12B_R, dacValue); // 设置DAC输出电压
			osDelay(300);  // 等待电压稳定
			//HAL_GPIO_WritePin(K_ON_GPIO_Port, K_ON_Pin, GPIO_PIN_SET); // 分压由20:1切换到2:1

			if (osSemaphoreAcquire(adcConversionCompleteSemaphoreHandle, 100)
					== osOK) {
				HandleADCData();
				parameters[number].holdingVoltage1 = voltageIn6 * 20.15;

				if (parameters[number].holdingVoltage1
						< parameters[number].holdingVoltage1LowerLimit
						|| parameters[number].holdingVoltage1
								> parameters[number].holdingVoltage1UpperLimit) {
					ok = false;
					currentResult.holdingVoltage1NG = true;  // 设置不良标志
					HAL_GPIO_WritePin(holdingVoltage1NG_GPIO_Port,
					holdingVoltage1NG_Pin, GPIO_PIN_RESET);
				}
			} else {
				ok = false;
				currentResult.holdingVoltage1NG = true;  // 设置不良标志
			}

//			// ------- 第三步：重复输入电压2，检测保持电压2（PA6） -------
//			dacValue = voltageToDAC(parameters[number].inputVoltage2);
//			HAL_DAC_SetValue(&hdac, DAC_CHANNEL_1, DAC_ALIGN_12B_R, dacValue); // 设置DAC输出电压
//			osDelay(300);  // 等待电压稳定
//
//			if (osSemaphoreAcquire(adcConversionCompleteSemaphoreHandle, 100)
//					== osOK) {
//				HandleADCData();
//				parameters[number].holdingVoltage2 = voltageIn6 * 20.15;
//
//				if (parameters[number].holdingVoltage2
//						< parameters[number].holdingVoltage2LowerLimit
//						|| parameters[number].holdingVoltage2
//								> parameters[number].holdingVoltage2UpperLimit) {
//					ok = false;
//					currentResult.holdingVoltage2NG = true;  // 设置不良标志
//					HAL_GPIO_WritePin(holdingVoltage2NG_GPIO_Port,
//					holdingVoltage2NG_Pin, GPIO_PIN_RESET);
//				}
//			} else {
//				ok = false;
//				currentResult.holdingVoltage2NG = true;  // 设置不良标志
//			}

			// ------- 第四步：输出输入电压3，检测保持电压3（PA6） -------
			dacValue = voltageToDAC(parameters[number].inputVoltage3);
			HAL_DAC_SetValue(&hdac, DAC_CHANNEL_1, DAC_ALIGN_12B_R, dacValue); // 设置DAC输出电压
			osDelay(300);  // 等待电压稳定

			if (osSemaphoreAcquire(adcConversionCompleteSemaphoreHandle, 100)
					== osOK) {
				HandleADCData();
				parameters[number].holdingVoltage3 = voltageIn6 * 20.15;

				if (parameters[number].holdingVoltage3
						< parameters[number].holdingVoltage3LowerLimit
						|| parameters[number].holdingVoltage3
								> parameters[number].holdingVoltage3UpperLimit) {
					ok = false;
					currentResult.holdingVoltage3NG = true;  // 设置不良标志
					HAL_GPIO_WritePin(holdingVoltage3NG_GPIO_Port,
					holdingVoltage3NG_Pin, GPIO_PIN_RESET);
				}
			} else {
				ok = false;
				currentResult.holdingVoltage3NG = true;  // 设置不良标志
			}

			// ------- 测试结果处理 -------
			if (ok) {
				productionCount.totalQualified++;  // 合格数量增加
				currentResult.testPassed = true;
				HAL_GPIO_WritePin(OK_GPIO_Port, OK_Pin, GPIO_PIN_RESET); // OK灯亮
			} else {
				productionCount.totalDefective++;  // 不合格数量增加
				currentResult.testPassed = false;
				HAL_GPIO_WritePin(NG_GPIO_Port, NG_Pin, GPIO_PIN_RESET); // NG灯亮
			}

			productionCount.totalProduction++;    // 总测试次数 +1
			currentResult.testFinished = true;
			SaveStatisticsToRTC(&productionCount);
			osDelay(200);
			HAL_GPIO_WritePin(NG_GPIO_Port, NG_Pin, GPIO_PIN_SET); // NG灯灭
		}

		HAL_GPIO_WritePin(LED0_GPIO_Port, LED0_Pin, GPIO_PIN_SET); // 关闭电压输出指示灯输出灯
		HAL_GPIO_WritePin(POWER_ON_GPIO_Port, POWER_ON_Pin, GPIO_PIN_SET); // 关闭电压输出
		osDelay(100);

	}
  /* USER CODE END testStartTask */
}

void SDCardManager(void *argument)
{
  /* USER CODE BEGIN SDCardManager */
	/* Infinite loop */
	//initSDCard();
	initNorFlash();
	GetDiskInfo();
//	AT24C02_Test();

	for (;;) {

//		loadParametersFromSDCard();
//	    osDelay(10000); //
//
//		saveParametersToSDCard();
//		osDelay(10000); //
//
//		loadStatisticsFromSDCard();
//	    osDelay(10000); //
//
//		saveStatisticsToSDCard();
//		osDelay(10000); //
//		ADS1115_Test();//i2c 测量电压模块

	}
	osDelay(3000);  // 周期检查每100ms
  /* USER CODE END SDCardManager */
}
